# ccg6df_cfp register map
Vendor: Infineon Technologies; Series: CCG6DF_CFP; File version: 1.0
CPU: CM0PLUS r0p1, little endian, MPU, no FPU, VTOR, 2 interrupt priority bits, 20 interrupts
Registers are 32-bit, read-write, reset 0x0 unless marked. A register's access mark holds for its fields unless they carry their own. Offsets are from the block's base; [hi:lo] are bit positions; {n}, {i} and the like mark numbered series.

## SPCIF — Flash Control Interface
Base 0x40110000
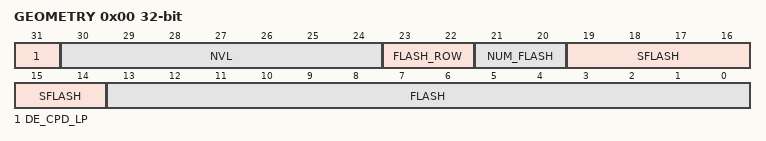
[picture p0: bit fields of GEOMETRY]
0x00 GEOMETRY (reset mask 0x80000000) — Flash/NVL geometry information
  [31] DE_CPD_LP — 0': SRAM busy wait loop has not been copied. '1': Busy wait loop has been written into SRAM.
  [30:24] NVL ro — NVLatch size in Byte multiples (chip dependent): '0': 0 Bytes '1': 1 Byte ... '127': 127 Bytes
  [23:22] FLASH_ROW ro — Page size in 64 Byte multiples (chip dependent): '0': 64 byte '1': 128 byte '2': 192 byte '3': 256 byte The page size is used to determine the number of Bytes in a page for Flash page based operations (e.g. PGM_PAGE). Note: the field name FLASH_ROW is misleading, as this field specifies the number of Bytes in a page, rather than the number of Bytes in a row. In a single plane flash macro architecture, a page consists of a single row. However, in a multi plane flash macro architecture, a page consists of multiple rows from different planes.
  [21:20] NUM_FLASH ro — Number of flash macros (chip dependent): '0': 1 flash macro '1': 2 flash macros '2': 3 flash macros '3': 4 flash macros
  [19:14] SFLASH ro — Supervisory flash capacity in 256 Byte multiples (chip dependent). If multiple flash macros are present, this field provides the supervisory flash capacity of all flash macros together: '0': 256 Bytes. '1': 2*256 Bytes. ... '63': 64*256 Bytes.
  [13:0] FLASH ro — Regular flash capacity in 256 Byte multiples (chip dependent). If multiple flash macros are present, this field provides the flash capacity of all flash macros together: '0': 256 Bytes. '1': 2*256 Bytes. ... '16383': 16384*256 Bytes.
0x1C NVL_WR_DATA — NVL write data register
  [7:0] DATA — Data to be written to NVLatch array
0x7F0 INTR — SPCIF interrupt request register
  [0] TIMER write-1-clears — Timer counter value reaches '0'. Set to '1', when event is detected. Write INTR field with '1', to clear bit. Write INTR_SET field with '1', to set bit.
0x7F4 INTR_SET — SPCIF interrupt set request register
  [0] TIMER write-1-sets — Write INTR_SET field with '1' to set corresponding INTR field.
0x7F8 INTR_MASK — SPCIF interrupt mask register
  [0] TIMER — Mask for corresponding field in INTR register.
0x7FC INTR_MASKED ro — SPCIF interrupt masked request register
  [0] TIMER — Logical and of corresponding request and mask fields.

## FPU — FPU interface
Base 0x40130000
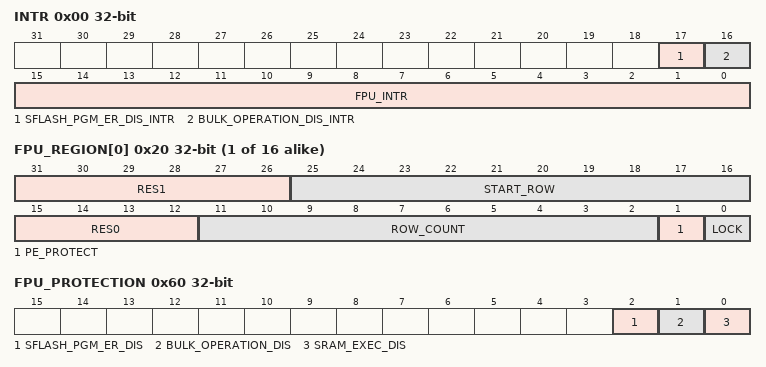
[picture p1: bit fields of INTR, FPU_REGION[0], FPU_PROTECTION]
0x00 INTR — FPU interrupt request register
  [17] SFLASH_PGM_ER_DIS_INTR write-1-clears — Atempt to erase/program/write sflash detected when disabled. Write '1' to this bit to clear.
  [16] BULK_OPERATION_DIS_INTR write-1-clears — Atempt to Bulk Operation (ERASE ALL) detected when disabled. Write '1' to this bit to clear.
  [15:0] FPU_INTR write-1-clears — Region write/erase protection interrupt, gets set at the erase state of a protected region, one bit for each region. Maximum of 16 regions supported, the number of regions available is product specific.
0x04 INTR_SET — FPU interrupt set request register
  [17:0] FPU_INTR_SET write-1-sets — Write INTR_SET field with '1' to set corresponding INTR field.
0x08 INTR_MASK — FPU interrupt mask register
  [17:0] FPU_INTR_MASK — Mask for corresponding field in INTR register.
0x0C INTR_MASKED ro — FPU interrupt masked request register
  [17:0] FPU_INTR_MASKED — Logical and of corresponding request and mask fields.
0x10 FPU_INFO ro — FPU configuration info register
  [4:0] FPU_INFO — number of available FPU regions
{0x20+4i} FPU_REGION[{i}] (i=0..15)
  [31:26] RES1 ro
  [25:16] START_ROW — Specifies the start of region being protected in terms of row number offset (only changeable when LOCK is cleared)
  [15:12] RES0 ro
  [11:2] ROW_COUNT — Specifies size of region being protected in terms of number of rows minus 1 (only changeable when LOCK is cleared) 0 --> 1 row 1 --> 2 rows ... 767 --> 768 rows
  [1] PE_PROTECT — '0': Program/Erase protection not enforced by the entry. '1': Program/Erase protection enforced for the entry. (only changeable when LOCK is cleared)
  [0] LOCK write-1-sets — '0': unlocked FPU entry, CPU can update the register fields '1': Lock - all FPU register fields are locked until next CPU reset
0x60 FPU_PROTECTION — SRAM execute disable register
  [2] SFLASH_PGM_ER_DIS write-1-sets — Disables programm/Erase/Write to SFLASH rows until device reset
  [1] BULK_OPERATION_DIS write-1-sets — Disables ERASE ALL for Flash memory until device reset
  [0] SRAM_EXEC_DIS write-1-sets — Disables excecution from SRAM until device reset
